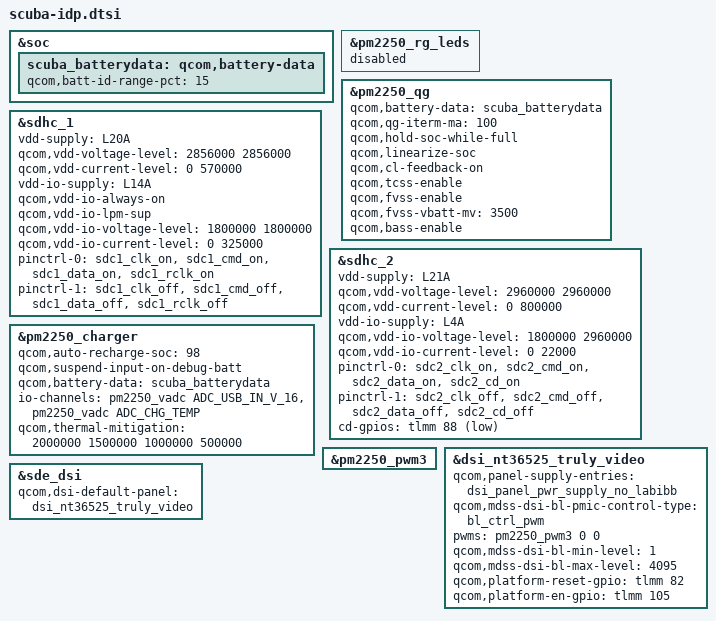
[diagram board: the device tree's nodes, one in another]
#include "scuba-audio-overlay.dtsi"
#include "scuba-thermal-overlay.dtsi"
#include <dt-bindings/gpio/gpio.h>
#include <dt-bindings/iio/qcom,spmi-vadc.h>
#include "scuba-sde-display.dtsi"

&soc {
	scuba_batterydata: qcom,battery-data {
		qcom,batt-id-range-pct = <15>;
		#include "qg-batterydata-alium-3600mah.dtsi"
		#include "qg-batterydata-atl466271_3300mAh.dtsi"
	};
};

&pm2250_rg_leds {
	status = "disabled";
};

&pm2250_qg {
	qcom,battery-data = <&scuba_batterydata>;
	qcom,qg-iterm-ma = <100>;
	qcom,hold-soc-while-full;
	qcom,linearize-soc;
	qcom,cl-feedback-on;
	qcom,tcss-enable;
	qcom,fvss-enable;
	qcom,fvss-vbatt-mv = <3500>;
	qcom,bass-enable;
};

&sdhc_1 {
	vdd-supply = <&L20A>;
	qcom,vdd-voltage-level = <2856000 2856000>;
	qcom,vdd-current-level = <0 570000>;

	vdd-io-supply = <&L14A>;
	qcom,vdd-io-always-on;
	qcom,vdd-io-lpm-sup;
	qcom,vdd-io-voltage-level = <1800000 1800000>;
	qcom,vdd-io-current-level = <0 325000>;

	pinctrl-names = "active", "sleep";
	pinctrl-0 = <&sdc1_clk_on &sdc1_cmd_on &sdc1_data_on
					&sdc1_rclk_on>;
	pinctrl-1 = <&sdc1_clk_off &sdc1_cmd_off &sdc1_data_off
					&sdc1_rclk_off>;

	status = "ok";
};

&sdhc_2 {
	vdd-supply = <&L21A>;
	qcom,vdd-voltage-level = <2960000 2960000>;
	qcom,vdd-current-level = <0 800000>;

	vdd-io-supply = <&L4A>;
	qcom,vdd-io-voltage-level = <1800000 2960000>;
	qcom,vdd-io-current-level = <0 22000>;

	pinctrl-names = "active", "sleep";
	pinctrl-0 = <&sdc2_clk_on  &sdc2_cmd_on &sdc2_data_on &sdc2_cd_on>;
	pinctrl-1 = <&sdc2_clk_off &sdc2_cmd_off &sdc2_data_off &sdc2_cd_off>;

	cd-gpios = <&tlmm 88 GPIO_ACTIVE_LOW>;

	status = "ok";
};

&pm2250_charger {
	qcom,auto-recharge-soc = <98>;
	qcom,suspend-input-on-debug-batt;
	qcom,battery-data = <&scuba_batterydata>;
	io-channels = <&pm2250_vadc ADC_USB_IN_V_16>,
			<&pm2250_vadc ADC_CHG_TEMP>;
	io-channel-names = "usb_in_voltage",
			"chg_temp";
	qcom,thermal-mitigation = <2000000 1500000 1000000 500000>;
};

&pm2250_pwm3 {
	status = "ok";
};

&dsi_nt36525_truly_video {
	qcom,panel-supply-entries = <&dsi_panel_pwr_supply_no_labibb>;
	qcom,mdss-dsi-bl-pmic-control-type = "bl_ctrl_pwm";
	pwms = <&pm2250_pwm3 0 0>;
	qcom,mdss-dsi-bl-min-level = <1>;
	qcom,mdss-dsi-bl-max-level = <4095>;
	qcom,platform-reset-gpio = <&tlmm 82 0>;
	qcom,platform-en-gpio = <&tlmm 105 0>;
};

&sde_dsi {
	qcom,dsi-default-panel = <&dsi_nt36525_truly_video>;
};
